VERSION ""

NS_ :

BS_:

BU_: Lighting_Rear Lighting_Right Lighting_Left Lighting_Front Lighting_Canopy Controls
VAL_TABLE_ Lighting_Board_Fault 0 "OK" 1 "Addr LED Undercurrent" 2 "LED0 Undercurrent" 3 "LED1 Undercurrent" 4 "Addr LED Overcurrent" 5 "LED0 Overcurrent" 6 "LED1 Overcurrent" 7 "Light Command Watchdog" 8 "Watchdog" ;
VAL_TABLE_ Lighting_CustomModes 0 "Off" 1 "Mode 1 Active" 2 "Mode 2 Active" 3 "Mode 3 Active" ;
VAL_TABLE_ Generic_OnOff 0 "Off" 1 "On" ;

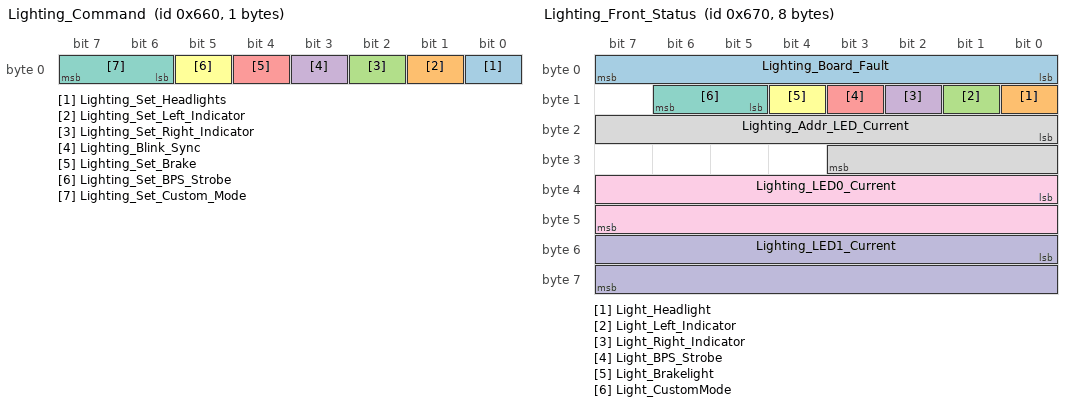
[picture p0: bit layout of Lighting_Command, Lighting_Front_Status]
BO_ 1632 Lighting_Command: 1 Controls
 SG_ Lighting_Set_Headlights : 0|1@1+ (1,0) [0|1] ""  Lighting_Right,Lighting_Left,Lighting_Canopy,Lighting_Rear,Lighting_Front
 SG_ Lighting_Set_Left_Indicator : 1|1@1+ (1,0) [0|1] ""  Lighting_Right,Lighting_Left,Lighting_Canopy,Lighting_Rear,Lighting_Front
 SG_ Lighting_Set_Right_Indicator : 2|1@1+ (1,0) [0|1] ""  Lighting_Right,Lighting_Left,Lighting_Canopy,Lighting_Rear,Lighting_Front
 SG_ Lighting_Blink_Sync : 3|1@1+ (1,0) [0|1] ""  Lighting_Right,Lighting_Left,Lighting_Canopy,Lighting_Rear,Lighting_Front
 SG_ Lighting_Set_Brake : 4|1@1+ (1,0) [0|1] ""  Lighting_Right,Lighting_Left,Lighting_Canopy,Lighting_Rear,Lighting_Front
 SG_ Lighting_Set_BPS_Strobe : 5|1@1+ (1,0) [0|1] ""  Lighting_Right,Lighting_Left,Lighting_Canopy,Lighting_Rear,Lighting_Front
 SG_ Lighting_Set_Custom_Mode : 6|2@1+ (1,0) [0|1] ""  Lighting_Right,Lighting_Left,Lighting_Canopy,Lighting_Rear,Lighting_Front

BO_ 1648 Lighting_Front_Status: 8 Lighting_Front
 SG_ Lighting_Board_Fault : 0|8@1+ (1,0) [0|255] ""  Controls
 SG_ Light_Headlight : 8|1@1+ (1,0) [0|1] ""  Controls
 SG_ Light_Left_Indicator : 9|1@1+ (1,0) [0|1] ""  Controls
 SG_ Light_Right_Indicator : 10|1@1+ (1,0) [0|1] ""  Controls
 SG_ Light_BPS_Strobe : 11|1@1+ (1,0) [0|1] ""  Controls
 SG_ Light_Brakelight : 12|1@1+ (1,0) [0|1] ""  Controls
 SG_ Light_CustomMode : 13|2@1+ (1,0) [0|1] ""  Controls
 SG_ Lighting_Addr_LED_Current : 16|12@1+ (0.001,0) [0|4.095] "A"  Controls
 SG_ Lighting_LED0_Current : 32|16@1+ (0.001,0) [0|65.535] "A"  Controls
 SG_ Lighting_LED1_Current : 48|16@1+ (0.001,0) [0|65.535] "A"  Controls

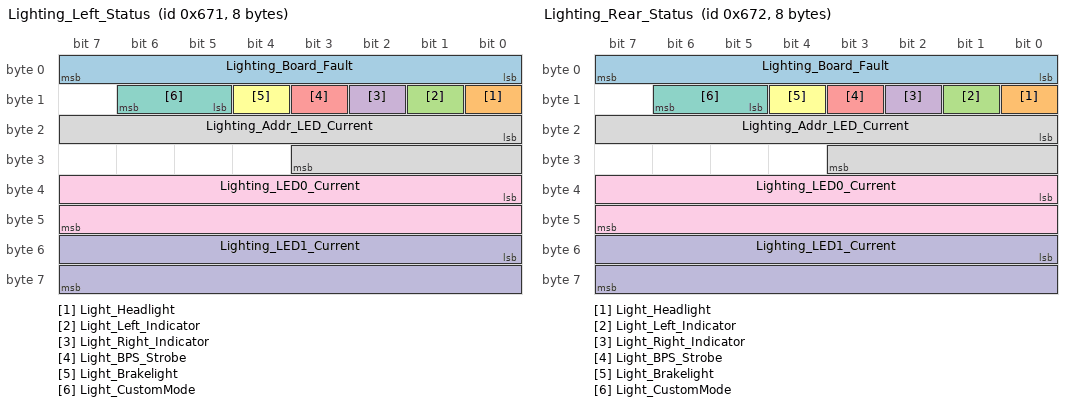
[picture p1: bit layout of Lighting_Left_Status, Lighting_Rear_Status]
BO_ 1649 Lighting_Left_Status: 8 Lighting_Left
 SG_ Lighting_Board_Fault : 0|8@1+ (1,0) [0|255] "" Vector__XXX
 SG_ Light_Headlight : 8|1@1+ (1,0) [0|1] "" Vector__XXX
 SG_ Light_Left_Indicator : 9|1@1+ (1,0) [0|1] "" Vector__XXX
 SG_ Light_Right_Indicator : 10|1@1+ (1,0) [0|1] "" Vector__XXX
 SG_ Light_BPS_Strobe : 11|1@1+ (1,0) [0|1] "" Vector__XXX
 SG_ Light_Brakelight : 12|1@1+ (1,0) [0|1] "" Vector__XXX
 SG_ Light_CustomMode : 13|2@1+ (1,0) [0|1] "" Vector__XXX
 SG_ Lighting_Addr_LED_Current : 16|12@1+ (0.001,0) [0|4.095] "A" Vector__XXX
 SG_ Lighting_LED0_Current : 32|16@1+ (0.001,0) [0|65.535] "A" Vector__XXX
 SG_ Lighting_LED1_Current : 48|16@1+ (0.001,0) [0|65.535] "A" Vector__XXX

BO_ 1650 Lighting_Rear_Status: 8 Lighting_Rear
 SG_ Lighting_Board_Fault : 0|8@1+ (1,0) [0|255] "" Vector__XXX
 SG_ Light_Headlight : 8|1@1+ (1,0) [0|1] "" Vector__XXX
 SG_ Light_Left_Indicator : 9|1@1+ (1,0) [0|1] "" Vector__XXX
 SG_ Light_Right_Indicator : 10|1@1+ (1,0) [0|1] "" Vector__XXX
 SG_ Light_BPS_Strobe : 11|1@1+ (1,0) [0|1] "" Vector__XXX
 SG_ Light_Brakelight : 12|1@1+ (1,0) [0|1] "" Vector__XXX
 SG_ Light_CustomMode : 13|2@1+ (1,0) [0|1] "" Vector__XXX
 SG_ Lighting_Addr_LED_Current : 16|12@1+ (0.001,0) [0|4.095] "A" Vector__XXX
 SG_ Lighting_LED0_Current : 32|16@1+ (0.001,0) [0|65.535] "A" Vector__XXX
 SG_ Lighting_LED1_Current : 48|16@1+ (0.001,0) [0|65.535] "A" Vector__XXX

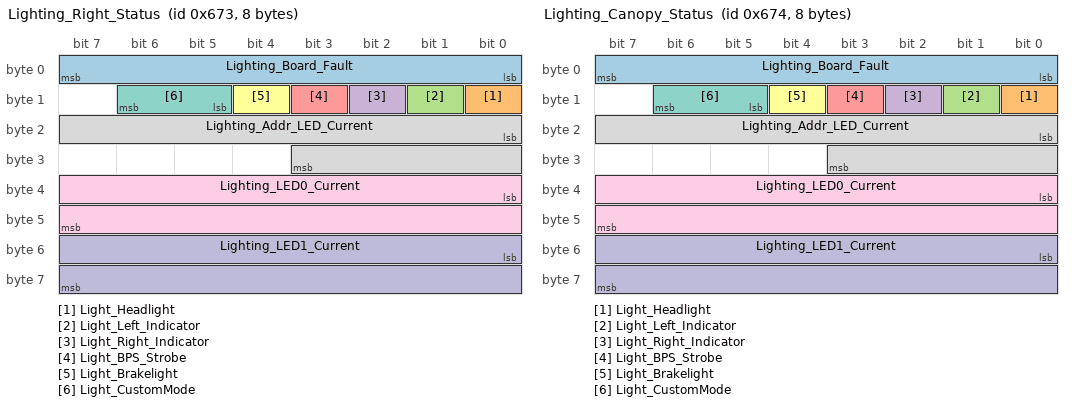
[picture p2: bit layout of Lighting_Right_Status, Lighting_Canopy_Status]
BO_ 1651 Lighting_Right_Status: 8 Lighting_Right
 SG_ Lighting_Board_Fault : 0|8@1+ (1,0) [0|255] "" Vector__XXX
 SG_ Light_Headlight : 8|1@1+ (1,0) [0|1] "" Vector__XXX
 SG_ Light_Left_Indicator : 9|1@1+ (1,0) [0|1] "" Vector__XXX
 SG_ Light_Right_Indicator : 10|1@1+ (1,0) [0|1] "" Vector__XXX
 SG_ Light_BPS_Strobe : 11|1@1+ (1,0) [0|1] "" Vector__XXX
 SG_ Light_Brakelight : 12|1@1+ (1,0) [0|1] "" Vector__XXX
 SG_ Light_CustomMode : 13|2@1+ (1,0) [0|1] "" Vector__XXX
 SG_ Lighting_Addr_LED_Current : 16|12@1+ (0.001,0) [0|4.095] "A" Vector__XXX
 SG_ Lighting_LED0_Current : 32|16@1+ (0.001,0) [0|65.535] "A" Vector__XXX
 SG_ Lighting_LED1_Current : 48|16@1+ (0.001,0) [0|65.535] "A" Vector__XXX

BO_ 1652 Lighting_Canopy_Status: 8 Lighting_Canopy
 SG_ Lighting_Board_Fault : 0|8@1+ (1,0) [0|255] "" Vector__XXX
 SG_ Light_Headlight : 8|1@1+ (1,0) [0|1] "" Vector__XXX
 SG_ Light_Left_Indicator : 9|1@1+ (1,0) [0|1] "" Vector__XXX
 SG_ Light_Right_Indicator : 10|1@1+ (1,0) [0|1] "" Vector__XXX
 SG_ Light_BPS_Strobe : 11|1@1+ (1,0) [0|1] "" Vector__XXX
 SG_ Light_Brakelight : 12|1@1+ (1,0) [0|1] "" Vector__XXX
 SG_ Light_CustomMode : 13|2@1+ (1,0) [0|1] "" Vector__XXX
 SG_ Lighting_Addr_LED_Current : 16|12@1+ (0.001,0) [0|4.095] "A" Vector__XXX
 SG_ Lighting_LED0_Current : 32|16@1+ (0.001,0) [0|65.535] "A" Vector__XXX
 SG_ Lighting_LED1_Current : 48|16@1+ (0.001,0) [0|65.535] "A" Vector__XXX

BA_DEF_  "DBName" STRING ;
BA_DEF_ BO_  "GenMsgSendType" ENUM  "Cyclic","Event","CyclicAndEvent","CyclicAndEventNoRepetition","None","Spontaneous";
BA_DEF_ BO_  "VFrameFormat" ENUM  "StandardCAN","ExtendedCAN","reserved","J1939PG","reserved","reserved","reserved","reserved","reserved","reserved","reserved","reserved","reserved","reserved","StandardCAN_FD","ExtendedCAN_FD";
BA_DEF_  "BusType" STRING ;
BA_DEF_DEF_  "DBName" "";
BA_DEF_DEF_  "GenMsgSendType" "Cyclic";
BA_DEF_DEF_  "VFrameFormat" "StandardCAN";
BA_DEF_DEF_  "BusType" "";
BA_ "BusType" "CAN";
BA_ "DBName" "LightingCAN";
VAL_ 1632 Lighting_Set_Headlights 0 "Off" 1 "On" ;
VAL_ 1632 Lighting_Set_Left_Indicator 0 "Off" 1 "On" ;
VAL_ 1632 Lighting_Set_Right_Indicator 0 "Off" 1 "On" ;
VAL_ 1632 Lighting_Set_Brake 0 "Off" 1 "On" ;
VAL_ 1632 Lighting_Set_BPS_Strobe 0 "Off" 1 "On" ;
VAL_ 1632 Lighting_Set_Custom_Mode 0 "Off" 1 "Mode 1 Active" 2 "Mode 2 Active" 3 "Mode 3 Active" ;
VAL_ 1648 Lighting_Board_Fault 0 "OK" 1 "Addr LED Undercurrent" 2 "LED0 Undercurrent" 3 "LED1 Undercurrent" 4 "Addr LED Overcurrent" 5 "LED0 Overcurrent" 6 "LED1 Overcurrent" 7 "Light Command Watchdog" 8 "Watchdog" ;
VAL_ 1648 Light_Headlight 0 "Off" 1 "On" ;
VAL_ 1648 Light_Left_Indicator 0 "Off" 1 "On" ;
VAL_ 1648 Light_Right_Indicator 0 "Off" 1 "On" ;
VAL_ 1648 Light_BPS_Strobe 0 "Off" 1 "On" ;
VAL_ 1648 Light_Brakelight 0 "Off" 1 "On" ;
VAL_ 1648 Light_CustomMode 0 "Off" 1 "On" ;
VAL_ 1649 Lighting_Board_Fault 0 "OK" 1 "Addr LED Undercurrent" 2 "LED0 Undercurrent" 3 "LED1 Undercurrent" 4 "Addr LED Overcurrent" 5 "LED0 Overcurrent" 6 "LED1 Overcurrent" 7 "Light Command Watchdog" 8 "Watchdog" ;
VAL_ 1649 Light_Headlight 0 "Off" 1 "On" ;
VAL_ 1649 Light_Left_Indicator 0 "Off" 1 "On" ;
VAL_ 1649 Light_Right_Indicator 0 "Off" 1 "On" ;
VAL_ 1649 Light_BPS_Strobe 0 "Off" 1 "On" ;
VAL_ 1649 Light_Brakelight 0 "Off" 1 "On" ;
VAL_ 1649 Light_CustomMode 0 "Off" 1 "On" ;
VAL_ 1650 Lighting_Board_Fault 0 "OK" 1 "Addr LED Undercurrent" 2 "LED0 Undercurrent" 3 "LED1 Undercurrent" 4 "Addr LED Overcurrent" 5 "LED0 Overcurrent" 6 "LED1 Overcurrent" 7 "Light Command Watchdog" 8 "Watchdog" ;
VAL_ 1650 Light_Headlight 0 "Off" 1 "On" ;
VAL_ 1650 Light_Left_Indicator 0 "Off" 1 "On" ;
VAL_ 1650 Light_Right_Indicator 0 "Off" 1 "On" ;
VAL_ 1650 Light_BPS_Strobe 0 "Off" 1 "On" ;
VAL_ 1650 Light_Brakelight 0 "Off" 1 "On" ;
VAL_ 1650 Light_CustomMode 0 "Off" 1 "On" ;
VAL_ 1651 Lighting_Board_Fault 0 "OK" 1 "Addr LED Undercurrent" 2 "LED0 Undercurrent" 3 "LED1 Undercurrent" 4 "Addr LED Overcurrent" 5 "LED0 Overcurrent" 6 "LED1 Overcurrent" 7 "Light Command Watchdog" 8 "Watchdog" ;
VAL_ 1651 Light_Headlight 0 "Off" 1 "On" ;
VAL_ 1651 Light_Left_Indicator 0 "Off" 1 "On" ;
VAL_ 1651 Light_Right_Indicator 0 "Off" 1 "On" ;
VAL_ 1651 Light_BPS_Strobe 0 "Off" 1 "On" ;
VAL_ 1651 Light_Brakelight 0 "Off" 1 "On" ;
VAL_ 1651 Light_CustomMode 0 "Off" 1 "On" ;
VAL_ 1652 Lighting_Board_Fault 0 "OK" 1 "Addr LED Undercurrent" 2 "LED0 Undercurrent" 3 "LED1 Undercurrent" 4 "Addr LED Overcurrent" 5 "LED0 Overcurrent" 6 "LED1 Overcurrent" 7 "Light Command Watchdog" 8 "Watchdog" ;
VAL_ 1652 Light_Headlight 0 "Off" 1 "On" ;
VAL_ 1652 Light_Left_Indicator 0 "Off" 1 "On" ;
VAL_ 1652 Light_Right_Indicator 0 "Off" 1 "On" ;
VAL_ 1652 Light_BPS_Strobe 0 "Off" 1 "On" ;
VAL_ 1652 Light_Brakelight 0 "Off" 1 "On" ;
VAL_ 1652 Light_CustomMode 0 "Off" 1 "On" ;
